# PIC32MK1024GPK064 device description
Architecture: MIPS; Family: PIC32MK; Series: PIC32MK
Registers are 32-bit, read-write, no defined reset value unless marked. A register's access mark holds for its fields unless they carry their own. Offsets are from the block's base; [hi:lo] are bit positions; {n}, {i} and the like mark numbered series; 'fields as' and 'values as' point back to an identical list.

## HLVD
Instances: HLVD 0x1f801800 in periph_pb1_std
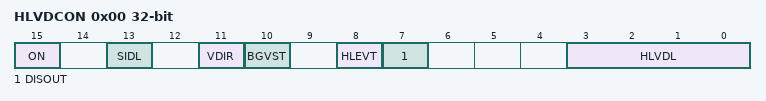
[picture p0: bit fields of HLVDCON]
0x00 HLVDCON — High/Low-Voltage Detect Control Register
  [15] ON — HLVD Module Enable bit
    1=HLVD module is enabled; 0=HLVD module is disabled
  [13] SIDL — Stop in Idle Mode bit
    1=Discontinue operation of LVD when device enters Idle mode; 0=Continue operation of LVD in Idle mode
  [11] VDIR — Voltage Change Direction Select bit
    1=Event occurs when voltage equals or exceeds the trip point (HLVDL); 0=Event occurs when voltage equals or falls below the trip point (HLVDL)
  [10] BGVST — Band Gap Reference Voltages Stable Status bit
    1=Indicates internal band gap voltage references is stable; 0=Indicates internal band gap voltage reference is not stable
  [8] HLEVT — High/Low-Voltage Detection Event Status bit
    1=Indicates HLVD Event is active; 0=Indicates HLVD Event is not active
  [7] DISOUT — Disable HLVD Output bit
    1=Enable output of HLVD Comparator. Once set, can only be cleared by setting the ON bit to 0.; 0=Disable output of HLVD Comparator (default Reset value)
  [3:0] HLVDL — High/Low-Voltage Detection Limit Select bits
    15=1.2V (Selects external LVDIN pin); 14=2.00V; 13=2.12V; 12=2.20V; 11=2.30V; 10=2.4V; 9=2.5V; 8=2.7V; 7=2.79V; 6=3.0V; 5=3.29V; 4=3.52V

## ICAP
Instances: ICAP 0x1f820000 in periph_pb2_std
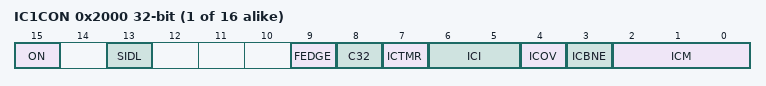
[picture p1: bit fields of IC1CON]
{0x1E00+0x200*i} IC{i}CON (i=1..16) — Input Capture x Control Register
  [15] ON — Input Capture Module Enable bit
    1=Module is enabled; 0=Disable and reset module
  [13] SIDL — Stop in Idle Control bit
    1=Halt in CPU Idle mode; 0=Continue to operate in CPU Idle mode
  [9] FEDGE — First Capture Edge Select bit
    1=Capture rising edge first; 0=Capture falling edge first
  [8] C32 — 32-bit Capture Select bit
    1=32-bit timer resource capture; 0=16-bit timer resource capture
  [7] ICTMR — Timer Select bit
    0=Timery is the counter source for capture; 1=Timerx is the counter source for capture
  [6:5] ICI — Interrupt Control bits
    3=Interrupt on every fourth capture event; 2=Interrupt on every third capture event; 1=Interrupt on every second capture event; 0=Interrupt on every capture event
  [4] ICOV — Input Capture Overflow Status Flag bit
    1=Input capture overflow is occurred; 0=No input capture overflow is occurred
  [3] ICBNE — Input Capture Buffer Not Empty Status bit
    1=Input capture buffer is not empty; at least one more capture value can be read; 0=Input capture buffer is empty
  [2:0] ICM — Input Capture Mode Select bits
    7=Interrupt-Only mode (only supported while in Sleep mode or Idle mode); 6=Simple Capture Event mode every edge; 5=Prescaled Capture Event mode every sixteenth rising edge; 4=Prescaled Capture Event mode every fourth rising edge; 3=Simple Capture Event mode every rising edge; 2=Simple Capture Event mode every falling edge; 1=Edge Detect mode every edge (rising and falling); 0=Input Capture module is disabled
{0x1E10+0x200*i} IC{i}BUF ro (i=1..16)

## JTAG
Instances: JTAG 0x1f801000 in periph_pb1_std
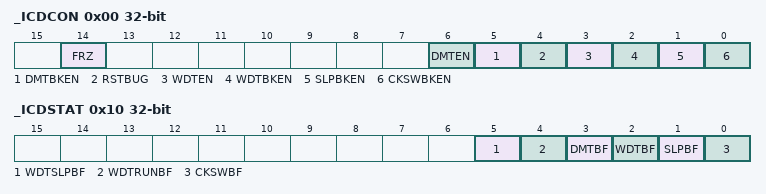
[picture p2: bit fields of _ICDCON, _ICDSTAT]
0x00 _ICDCON
  [14] FRZ, [6] DMTEN, [5] DMTBKEN, [4] RSTBUG, [3] WDTEN, [2] WDTBKEN, [1] SLPBKEN, [0] CKSWBKEN
0x10 _ICDSTAT
  [5] WDTSLPBF, [4] WDTRUNBF, [3] DMTBF, [2] WDTBF, [1] SLPBF, [0] CKSWBF

## OCMP
Instances: OCMP 0x1f820000 in periph_pb2_std
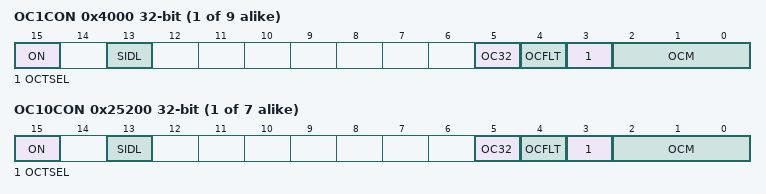
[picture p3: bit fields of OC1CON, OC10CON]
{0x3E00+0x200*i} OC{i}CON (i=1..9) — Output Compare 'x' Control Register
  [15] ON — Output Compare Peripheral On bit
    1=Output Compare peripheral is enabled; 0=Output Compare peripheral is disabled
  [13] SIDL — Stop in Idle Mode bit
    1=Discontinue operation when CPU enters Idle mode; 0=Continue operation in Idle mode
  [5] OC32 — 32-bit Compare Mode bit
    1=OCxR and/or OCxRS are used for comparisions to the 32-bit timer source; 0=OCxR and OCxRS are used for comparisons to the 16-bit timer source
  [4] OCFLT — PWM Fault Condition Status bit(1)
    1=PWM Fault condition has occurred (cleared in HW only); 0=No PWM Fault condition has occurred
  [3] OCTSEL — Output Compare Timer Select bit(2)
    1=Timery is the clock source for this Output Compare module; 0=Timerx is the clock source for this Output Compare module
  [2:0] OCM — Output Compare Mode Select bits
    7=PWM mode on OCx; Fault pin enabled; 6=PWM mode on OCx; Fault pin disabled; 5=Initialize OCx pin low; generate continuous output pulses on OCx pin; 4=Initialize OCx pin low: generate single output pulse on OCx pin; 3=Compare event toggles OCx pin; 2=Initialize OCx pin high ; compare event forces OCx pin low; 1=Initialize OCx pin low; compare event forces OCx pin high; 0=Output compare peripheral is disabled but continues to draw current
{0x3E10+0x200*i} OC{i}R (i=1..9)
{0x3E20+0x200*i} OC{i}RS (i=1..9)
{0x23E00+0x200*i} OC{i}CON (i=10..16) — Output Compare 'x' Control Register
  fields as OC1CON
{0x23E10+0x200*i} OC{i}R (i=10..16)
{0x23E20+0x200*i} OC{i}RS (i=10..16)
